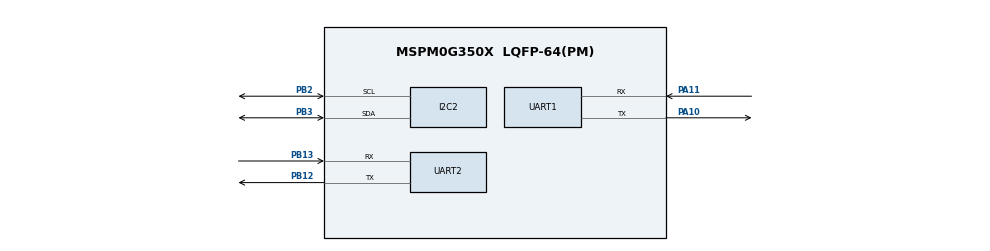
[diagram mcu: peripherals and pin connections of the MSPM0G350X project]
/**
 * @cliArgs --device "MSPM0G350X" --part "Default" --package "LQFP-64(PM)" --product "mspm0_sdk@2.02.00.05"
 * @versions {"tool":"1.21.1+3772"}
 */

/**
 * Import the modules used in this configuration.
 */
const GPIO   = scripting.addModule("/ti/driverlib/GPIO", {}, false);
const GPIO1  = GPIO.addInstance();
const GPIO2  = GPIO.addInstance();
const I2C    = scripting.addModule("/ti/driverlib/I2C", {}, false);
const I2C1   = I2C.addInstance();
const I2C2   = I2C.addInstance();
const SYSCTL = scripting.addModule("/ti/driverlib/SYSCTL");
const TIMER  = scripting.addModule("/ti/driverlib/TIMER", {}, false);
const TIMER1 = TIMER.addInstance();
const UART   = scripting.addModule("/ti/driverlib/UART", {}, false);
const UART1  = UART.addInstance();
const UART2  = UART.addInstance();

/**
 * Write custom configuration values to the imported modules.
 */
const gate7  = system.clockTree["MFCLKGATE"];
gate7.enable = true;

const mux8       = system.clockTree["HSCLKMUX"];
mux8.inputSelect = "HSCLKMUX_SYSPLL0";

const pinFunction4     = system.clockTree["HFXT"];
pinFunction4.inputFreq = 40;
pinFunction4.enable    = true;

GPIO1.$name                              = "LED1";
GPIO1.associatedPins[0].internalResistor = "PULL_DOWN";
GPIO1.associatedPins[0].$name            = "Green";
GPIO1.associatedPins[0].assignedPin      = "26";
GPIO1.associatedPins[0].assignedPort     = "PORTA";

const Board = scripting.addModule("/ti/driverlib/Board", {}, false);

GPIO2.$name                          = "KEY";
GPIO2.associatedPins[0].direction    = "INPUT";
GPIO2.associatedPins[0].ioStructure  = "SD";
GPIO2.associatedPins[0].assignedPort = "PORTB";
GPIO2.associatedPins[0].assignedPin  = "14";
GPIO2.associatedPins[0].$name        = "key2";

I2C1.basicEnableController             = true;
I2C1.basicControllerStandardBusSpeed   = "Fast";
I2C1.$name                             = "I2C_OLED";
I2C1.sdaPinConfig.hideOutputInversion  = scripting.forceWrite(false);
I2C1.sdaPinConfig.onlyInternalResistor = scripting.forceWrite(false);
I2C1.sdaPinConfig.passedPeripheralType = scripting.forceWrite("Digital");
I2C1.sdaPinConfig.$name                = "ti_driverlib_gpio_GPIOPinGeneric2";
I2C1.sclPinConfig.hideOutputInversion  = scripting.forceWrite(false);
I2C1.sclPinConfig.onlyInternalResistor = scripting.forceWrite(false);
I2C1.sclPinConfig.passedPeripheralType = scripting.forceWrite("Digital");
I2C1.sclPinConfig.$name                = "ti_driverlib_gpio_GPIOPinGeneric3";

I2C2.basicEnableController             = true;
I2C2.basicControllerStandardBusSpeed   = "Fast";
I2C2.$name                             = "I2C_MAX";
I2C2.peripheral.sdaPin.$assign         = "PB3";
I2C2.peripheral.sclPin.$assign         = "PB2";
I2C2.sdaPinConfig.hideOutputInversion  = scripting.forceWrite(false);
I2C2.sdaPinConfig.onlyInternalResistor = scripting.forceWrite(false);
I2C2.sdaPinConfig.passedPeripheralType = scripting.forceWrite("Digital");
I2C2.sdaPinConfig.$name                = "ti_driverlib_gpio_GPIOPinGeneric6";
I2C2.sclPinConfig.hideOutputInversion  = scripting.forceWrite(false);
I2C2.sclPinConfig.onlyInternalResistor = scripting.forceWrite(false);
I2C2.sclPinConfig.passedPeripheralType = scripting.forceWrite("Digital");
I2C2.sclPinConfig.$name                = "ti_driverlib_gpio_GPIOPinGeneric7";

SYSCTL.forceDefaultClkConfig = true;
SYSCTL.clockTreeEn           = true;

TIMER1.$name     = "TIMER_0";
TIMER1.timerMode = "PERIODIC_UP";

UART1.$name                    = "UART_0";
UART1.enabledInterrupts        = ["RX"];
UART1.uartClkSrc               = "MFCLK";
UART1.peripheral.rxPin.$assign = "PA11";
UART1.peripheral.txPin.$assign = "PA10";
UART1.txPinConfig.$name        = "ti_driverlib_gpio_GPIOPinGeneric0";
UART1.rxPinConfig.$name        = "ti_driverlib_gpio_GPIOPinGeneric1";

UART2.uartClkSrc                       = "MFCLK";
UART2.enabledInterrupts                = ["RX"];
UART2.targetBaudRate                   = 115200;
UART2.$name                            = "UART_3";
UART2.peripheral.$assign               = "UART3";
UART2.peripheral.rxPin.$assign         = "PB13";
UART2.peripheral.txPin.$assign         = "PB12";
UART2.txPinConfig.direction            = scripting.forceWrite("OUTPUT");
UART2.txPinConfig.hideOutputInversion  = scripting.forceWrite(false);
UART2.txPinConfig.onlyInternalResistor = scripting.forceWrite(false);
UART2.txPinConfig.passedPeripheralType = scripting.forceWrite("Digital");
UART2.txPinConfig.$name                = "ti_driverlib_gpio_GPIOPinGeneric4";
UART2.rxPinConfig.hideOutputInversion  = scripting.forceWrite(false);
UART2.rxPinConfig.onlyInternalResistor = scripting.forceWrite(false);
UART2.rxPinConfig.passedPeripheralType = scripting.forceWrite("Digital");
UART2.rxPinConfig.$name                = "ti_driverlib_gpio_GPIOPinGeneric5";

/**
 * Pinmux solution for unlocked pins/peripherals. This ensures that minor changes to the automatic solver in a future
 * version of the tool will not impact the pinmux you originally saw.  These lines can be completely deleted in order to
 * re-solve from scratch.
 */
pinFunction4.peripheral.$suggestSolution           = "SYSCTL";
pinFunction4.peripheral.hfxInPin.$suggestSolution  = "PA5";
pinFunction4.peripheral.hfxOutPin.$suggestSolution = "PA6";
GPIO1.associatedPins[0].pin.$suggestSolution       = "PA26";
Board.peripheral.$suggestSolution                  = "DEBUGSS";
Board.peripheral.swclkPin.$suggestSolution         = "PA20";
Board.peripheral.swdioPin.$suggestSolution         = "PA19";
GPIO2.associatedPins[0].pin.$suggestSolution       = "PB14";
I2C1.peripheral.$suggestSolution                   = "I2C0";
I2C1.peripheral.sdaPin.$suggestSolution            = "PA0";
I2C1.peripheral.sclPin.$suggestSolution            = "PA1";
I2C2.peripheral.$suggestSolution                   = "I2C1";
TIMER1.peripheral.$suggestSolution                 = "TIMA0";
UART1.peripheral.$suggestSolution                  = "UART0";
